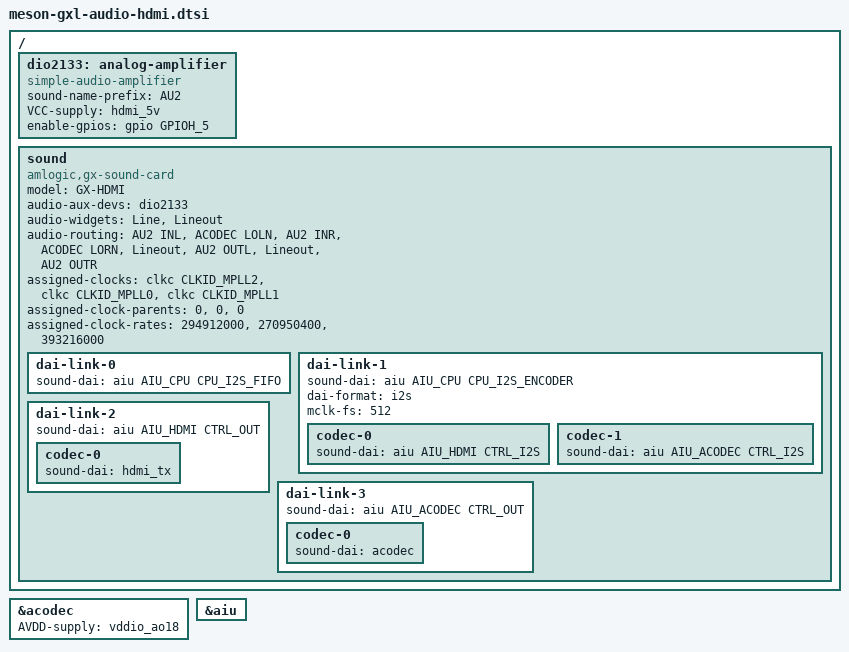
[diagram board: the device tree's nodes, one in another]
// SPDX-License-Identifier: (GPL-2.0+ OR MIT)
/*
 * Copyright (c) 2019 Christian Hewitt <christianshewitt@gmail.com>
 */

#include <dt-bindings/sound/meson-aiu.h>

/ {
	dio2133: analog-amplifier {
		compatible = "simple-audio-amplifier";
		sound-name-prefix = "AU2";
		VCC-supply = <&hdmi_5v>;
		enable-gpios = <&gpio GPIOH_5 GPIO_ACTIVE_HIGH>;
	};

	sound {
		compatible = "amlogic,gx-sound-card";
		model = "GX-HDMI";
		audio-aux-devs = <&dio2133>;
		audio-widgets = "Line", "Lineout";
		audio-routing = "AU2 INL", "ACODEC LOLN",
				"AU2 INR", "ACODEC LORN",
				"Lineout", "AU2 OUTL",
				"Lineout", "AU2 OUTR";
		assigned-clocks = <&clkc CLKID_MPLL2>,
				  <&clkc CLKID_MPLL0>,
				  <&clkc CLKID_MPLL1>;
		assigned-clock-parents = <0>, <0>, <0>;
		assigned-clock-rates = <294912000>,
				       <270950400>,
				       <393216000>;
		status = "okay";

		dai-link-0 {
			sound-dai = <&aiu AIU_CPU CPU_I2S_FIFO>;
		};

		dai-link-1 {
			sound-dai = <&aiu AIU_CPU CPU_I2S_ENCODER>;
			dai-format = "i2s";
			mclk-fs = <512>;

			codec-0 {
				sound-dai = <&aiu AIU_HDMI CTRL_I2S>;
			};

			codec-1 {
				sound-dai = <&aiu AIU_ACODEC CTRL_I2S>;
			};
		};

		dai-link-2 {
			sound-dai = <&aiu AIU_HDMI CTRL_OUT>;

			codec-0 {
				sound-dai = <&hdmi_tx>;
			};
		};

		dai-link-3 {
			sound-dai = <&aiu AIU_ACODEC CTRL_OUT>;

			codec-0 {
				sound-dai = <&acodec>;
			};
		};
	};
};

&acodec {
	AVDD-supply = <&vddio_ao18>;
	status = "okay";
};

&aiu {
	status = "okay";
};
